VERSION ""

BU_:

BO_ 919 ContactorRequest: 4 Vector__XXX
 SG_ MainContactorPos : 0|8@1+ (1,0) [0|1] "" Vector__XXX
 SG_ MainContactorNeg : 8|8@1+ (1,0) [0|1] "" Vector__XXX

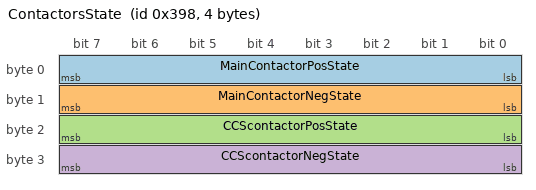
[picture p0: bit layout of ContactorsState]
BO_ 920 ContactorsState: 4 Vector__XXX
 SG_ MainContactorPosState : 0|8@1+ (1,0) [0|2] "" Vector__XXX
 SG_ MainContactorNegState : 8|8@1+ (1,0) [0|2] "" Vector__XXX
 SG_ CCScontactorPosState : 16|8@1+ (1,0) [0|2] "" Vector__XXX
 SG_ CCScontactorNegState : 24|8@1+ (1,0) [0|2] "" Vector__XXX

VAL_ 919 MainContactorPos 0 "REQUEST_OPEN" 1 "REQUEST_CLOSE" ;
VAL_ 919 MainContactorNeg 0 "REQUEST_OPEN" 1 "REQUEST_CLOSE" ;

VAL_ 920 MainContactorPosState 0 "OPEN" 1 "STARTUP" 2 "ECONOMIZED" ;
VAL_ 920 MainContactorNegState 0 "OPEN" 1 "STARTUP" 2 "ECONOMIZED" ;
VAL_ 920 CCScontactorPosState 0 "OPEN" 1 "STARTUP" 2 "ECONOMIZED" ;
VAL_ 920 CCScontactorNegState 0 "OPEN" 1 "STARTUP" 2 "ECONOMIZED" ;
